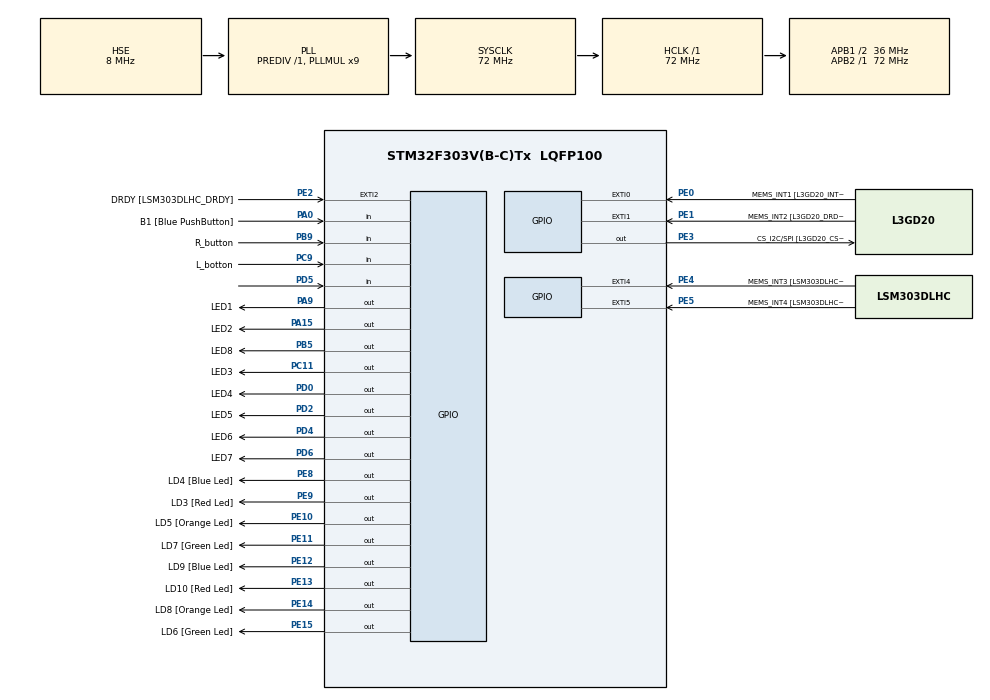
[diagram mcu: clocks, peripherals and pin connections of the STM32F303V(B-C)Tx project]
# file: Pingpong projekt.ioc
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Mcu.Family=STM32F3
Mcu.Name=STM32F303V(B-C)Tx
Mcu.Package=LQFP100
NVIC.PriorityGroup=NVIC_PRIORITYGROUP_0
PA0.GPIO_Label=B1 [Blue PushButton]
PA0.GPIO_Mode=GPIO_MODE_INPUT
PA0.GPIO_PuPd=GPIO_NOPULL
PA0.Signal=GPIO_Input
PA11.GPIO_Label=DM
PA11.Signal=USB_DM
PA12.GPIO_Label=DP
PA12.Signal=USB_DP
PA13.GPIO_Label=SWDIO
PA13.Signal=SYS_JTMS-SWDIO
PA14.GPIO_Label=SWCLK
PA14.Signal=SYS_JTCK-SWCLK
PA15.GPIO_Label=LED2
PA15.GPIO_Speed=GPIO_SPEED_FREQ_MEDIUM
PA15.Signal=GPIO_Output
PA5.GPIO_Label=SPI1_SCK [L3GD20_SCL/SPC]
PA5.GPIO_Mode=GPIO_MODE_AF_PP
PA5.GPIO_PuPd=GPIO_NOPULL
PA5.GPIO_Speed=GPIO_SPEED_FREQ_LOW
PA5.Signal=SPI1_SCK
PA6.GPIO_Label=SPI1_MISO [L3GD20_SA0/SDO]
PA6.GPIO_Mode=GPIO_MODE_AF_PP
PA6.GPIO_PuPd=GPIO_NOPULL
PA6.GPIO_Speed=GPIO_SPEED_FREQ_LOW
PA6.Signal=SPI1_MISO
PA7.GPIO_Label=SPI1_MISO [L3GD20_SDA/SDI/SDO]
PA7.GPIO_Mode=GPIO_MODE_AF_PP
PA7.GPIO_PuPd=GPIO_NOPULL
PA7.GPIO_Speed=GPIO_SPEED_FREQ_LOW
PA7.Signal=SPI1_MOSI
PA9.GPIO_Label=LED1
PA9.GPIO_Speed=GPIO_SPEED_FREQ_MEDIUM
PA9.Signal=GPIO_Output
PB3.GPIO_Label=SWO
PB3.Signal=SYS_JTDO-TRACESWO
PB5.GPIO_Label=LED8
PB5.GPIO_Speed=GPIO_SPEED_FREQ_MEDIUM
PB5.Signal=GPIO_Output
PB6.GPIO_FM6=__NULL
PB6.GPIO_Label=I2C1_SCL [LSM303DLHC_SCL]
PB6.GPIO_Mode=GPIO_MODE_AF_OD
PB6.GPIO_PuPd=GPIO_NOPULL
PB6.GPIO_Speed=GPIO_SPEED_FREQ_LOW
PB6.Signal=I2C1_SCL
PB7.GPIO_FM7=__NULL
PB7.GPIO_Label=I2C1_SDA [LSM303DLHC_SDA]
PB7.GPIO_Mode=GPIO_MODE_AF_OD
PB7.GPIO_PuPd=GPIO_NOPULL
PB7.GPIO_Speed=GPIO_SPEED_FREQ_LOW
PB7.Signal=I2C1_SDA
PB9.GPIO_Label=R_button
PB9.Signal=GPIO_Input
PC11.GPIO_Label=LED3
PC11.GPIO_Speed=GPIO_SPEED_FREQ_MEDIUM
PC11.Signal=GPIO_Output
PC14-OSC32_IN.GPIO_Label=OSC32_IN
PC14-OSC32_IN.Signal=RCC_OSC32_IN
PC15-OSC32_OUT.GPIO_Label=OSC32_OUT
PC15-OSC32_OUT.Signal=RCC_OSC32_OUT
PC9.GPIO_Label=L_botton
PC9.Signal=GPIO_Input
PD0.GPIO_Label=LED4
PD0.GPIO_Speed=GPIO_SPEED_FREQ_MEDIUM
PD0.Signal=GPIO_Output
PD2.GPIO_Label=LED5
PD2.GPIO_Speed=GPIO_SPEED_FREQ_MEDIUM
PD2.Signal=GPIO_Output
PD4.GPIO_Label=LED6
PD4.GPIO_Speed=GPIO_SPEED_FREQ_MEDIUM
PD4.Signal=GPIO_Output
PD5.Signal=GPIO_Input
PD6.GPIO_Label=LED7
PD6.GPIO_Speed=GPIO_SPEED_FREQ_MEDIUM
PD6.Signal=GPIO_Output
PE0.GPIO_Label=MEMS_INT1 [L3GD20_INT1]
PE0.GPIO_ModeDefaultEXTI=GPIO_MODE_EVT_RISING
PE0.GPIO_PuPd=GPIO_NOPULL
PE0.Signal=GPXTI0
PE1.GPIO_Label=MEMS_INT2 [L3GD20_DRDY/INT2]
PE1.GPIO_ModeDefaultEXTI=GPIO_MODE_EVT_RISING
PE1.GPIO_PuPd=GPIO_NOPULL
PE1.Signal=GPXTI1
PE10.GPIO_Label=LD5 [Orange Led]
PE10.GPIO_ModeDefaultOutputPP=GPIO_MODE_OUTPUT_PP
PE10.GPIO_PuPd=GPIO_NOPULL
PE10.GPIO_Speed=GPIO_SPEED_FREQ_LOW
PE10.Signal=GPIO_Output
PE11.GPIO_Label=LD7 [Green Led]
PE11.GPIO_ModeDefaultOutputPP=GPIO_MODE_OUTPUT_PP
PE11.GPIO_PuPd=GPIO_NOPULL
PE11.GPIO_Speed=GPIO_SPEED_FREQ_LOW
PE11.Signal=GPIO_Output
PE12.GPIO_Label=LD9 [Blue Led]
PE12.GPIO_ModeDefaultOutputPP=GPIO_MODE_OUTPUT_PP
PE12.GPIO_PuPd=GPIO_NOPULL
PE12.GPIO_Speed=GPIO_SPEED_FREQ_LOW
PE12.Signal=GPIO_Output
PE13.GPIO_Label=LD10 [Red Led]
PE13.GPIO_ModeDefaultOutputPP=GPIO_MODE_OUTPUT_PP
PE13.GPIO_PuPd=GPIO_NOPULL
PE13.GPIO_Speed=GPIO_SPEED_FREQ_LOW
PE13.Signal=GPIO_Output
PE14.GPIO_Label=LD8 [Orange Led]
PE14.GPIO_ModeDefaultOutputPP=GPIO_MODE_OUTPUT_PP
PE14.GPIO_PuPd=GPIO_NOPULL
PE14.GPIO_Speed=GPIO_SPEED_FREQ_LOW
PE14.Signal=GPIO_Output
PE15.GPIO_Label=LD6 [Green Led]
PE15.GPIO_ModeDefaultOutputPP=GPIO_MODE_OUTPUT_PP
PE15.GPIO_PuPd=GPIO_NOPULL
PE15.GPIO_Speed=GPIO_SPEED_FREQ_LOW
PE15.Signal=GPIO_Output
PE2.GPIO_Label=DRDY [LSM303DLHC_DRDY]
PE2.GPIO_ModeDefaultEXTI=GPIO_MODE_EVT_RISING
PE2.GPIO_PuPd=GPIO_NOPULL
PE2.Signal=GPXTI2
PE3.GPIO_Label=CS_I2C/SPI [L3GD20_CS_I2C/SPI]
PE3.GPIO_ModeDefaultOutputPP=GPIO_MODE_OUTPUT_PP
PE3.GPIO_PuPd=GPIO_NOPULL
PE3.GPIO_Speed=GPIO_SPEED_FREQ_LOW
PE3.Signal=GPIO_Output
PE4.GPIO_Label=MEMS_INT3 [LSM303DLHC_INT1]
PE4.GPIO_ModeDefaultEXTI=GPIO_MODE_EVT_RISING
PE4.GPIO_PuPd=GPIO_NOPULL
PE4.Signal=GPXTI4
PE5.GPIO_Label=MEMS_INT4 [LSM303DLHC_INT2]
PE5.GPIO_ModeDefaultEXTI=GPIO_MODE_EVT_RISING
PE5.GPIO_PuPd=GPIO_NOPULL
PE5.Signal=GPXTI5
PE8.GPIO_Label=LD4 [Blue Led]
PE8.GPIO_ModeDefaultOutputPP=GPIO_MODE_OUTPUT_PP
PE8.GPIO_PuPd=GPIO_NOPULL
PE8.GPIO_Speed=GPIO_SPEED_FREQ_LOW
PE8.Signal=GPIO_Output
PE9.GPIO_Label=LD3 [Red Led]
PE9.GPIO_ModeDefaultOutputPP=GPIO_MODE_OUTPUT_PP
PE9.GPIO_PuPd=GPIO_NOPULL
PE9.GPIO_Speed=GPIO_SPEED_FREQ_LOW
PE9.Signal=GPIO_Output
PF0-OSC_IN.Mode=HSE-External-Oscillator
PF0-OSC_IN.Signal=RCC_OSC_IN
PF1-OSC_OUT.GPIO_Label=OSC_OUT
PF1-OSC_OUT.Mode=HSE-External-Oscillator
PF1-OSC_OUT.Signal=RCC_OSC_OUT
ProjectManager.HeapSize=0x200
ProjectManager.StackSize=0x400
ProjectManager.TargetToolchain=EWARM
RCC.AHBFreq_Value=72000000
RCC.APB1CLKDivider=RCC_HCLK_DIV2
RCC.APB1Freq_Value=36000000
RCC.APB1TimFreq_Value=72000000
RCC.APB2Freq_Value=72000000
RCC.APB2TimFreq_Value=72000000
RCC.CortexFreq_Value=72000000
RCC.HCLKFreq_Value=72000000
RCC.HSE_VALUE=8000000
RCC.HSIState=RCC_HSI_ON
RCC.HSI_VALUE=8000000
RCC.LSE_VALUE=32768
RCC.PLLMUL=RCC_PLL_MUL9
RCC.PLLSourceVirtual=RCC_PLLSOURCE_HSE
RCC.SYSCLKFreq_VALUE=72000000
RCC.SYSCLKSourceVirtual=RCC_SYSCLKSOURCE_PLLCLK
RCC.USBFreq_Value=72000000
board=STM32F3DISCOVERY

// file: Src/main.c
/**
  ******************************************************************************
  * File Name          : main.c
  * Description        : Main program body
  ******************************************************************************
  *
  * COPYRIGHT(c) 2017 STMicroelectronics
  *
  * Redistribution and use in source and binary forms, with or without modification,
  * are permitted provided that the following conditions are met:
  *   1. Redistributions of source code must retain the above copyright notice,
  *      this list of conditions and the following disclaimer.
  *   2. Redistributions in binary form must reproduce the above copyright notice,
  *      this list of conditions and the following disclaimer in the documentation
  *      and/or other materials provided with the distribution.
  *   3. Neither the name of STMicroelectronics nor the names of its contributors
  *      may be used to endorse or promote products derived from this software
  *      without specific prior written permission.
  *
  * THIS SOFTWARE IS PROVIDED BY THE COPYRIGHT HOLDERS AND CONTRIBUTORS "AS IS"
  * AND ANY EXPRESS OR IMPLIED WARRANTIES, INCLUDING, BUT NOT LIMITED TO, THE
  * IMPLIED WARRANTIES OF MERCHANTABILITY AND FITNESS FOR A PARTICULAR PURPOSE ARE
  * DISCLAIMED. IN NO EVENT SHALL THE COPYRIGHT HOLDER OR CONTRIBUTORS BE LIABLE
  * FOR ANY DIRECT, INDIRECT, INCIDENTAL, SPECIAL, EXEMPLARY, OR CONSEQUENTIAL
  * DAMAGES (INCLUDING, BUT NOT LIMITED TO, PROCUREMENT OF SUBSTITUTE GOODS OR
  * SERVICES; LOSS OF USE, DATA, OR PROFITS; OR BUSINESS INTERRUPTION) HOWEVER
  * CAUSED AND ON ANY THEORY OF LIABILITY, WHETHER IN CONTRACT, STRICT LIABILITY,
  * OR TORT (INCLUDING NEGLIGENCE OR OTHERWISE) ARISING IN ANY WAY OUT OF THE USE
  * OF THIS SOFTWARE, EVEN IF ADVISED OF THE POSSIBILITY OF SUCH DAMAGE.
  *
  ******************************************************************************
  */
#include "main.h"
#include "stm32f3xx_hal.h"
#include "stdbool.h"
#include "Pingpong_functions.c"

/* USER CODE BEGIN PV */
/* Private variables ---------------------------------------------------------*/

/* USER CODE END PV */

void SystemClock_Config(void);
void Error_Handler(void);
static void MX_GPIO_Init(void);

/* USER CODE BEGIN PFP */
/* Private function prototypes -----------------------------------------------*/

typedef enum
{ Start,
MoveRight,
MoveLeft,
ShowPoints
} states;

states State, NextState;

/* USER CODE END PFP */

int main(void)
{

  bool ButtonPressed; // To remember that button is pressed
  bool surf;

  uint32_t Varv, Speed; // Ball speed
  uint8_t Led; // LED nr

  State= Start; // Initiate State to Start
  NextState= Start;
  int lp = 0;
  int rp = 0;

 Speed= 500000; // Number of loops

  /* Reset of all peripherals, Initializes the Flash interface and the Systick. */
  HAL_Init();

  /* Configure the system clock */
  SystemClock_Config();

  /* Initialize all configured peripherals */
  MX_GPIO_Init();

  while (1)
 {
   State = NextState;

   switch (State) // State machine
   {
     case Start:

     Led_on(0); // Turn off all LEDs
     HAL_GPIO_WritePin(LED1_GPIO_Port, LED1_Pin, GPIO_PIN_SET);
     HAL_GPIO_WritePin(LED8_GPIO_Port, LED8_Pin, GPIO_PIN_SET);
     HAL_Delay(1);
     Led_on(0);
     HAL_Delay(10);

     if ( L_hit() == true ) // L serve
     {
       Led = 1;
       surf = false;
       NextState= MoveRight;
       while ( L_hit() == true ); // wait until button is released
     }
     else if ( R_hit() == true ) // R serve
     {
       surf = true;
       Led = 8;
       NextState= MoveLeft;

       while ( R_hit() == true ); // wait until button is released
     }
     else
     NextState = Start; // Stay in Start state
     break;

 case MoveRight:
 {
   Led_on(Led);
   Varv = Speed;

   while( Varv != 0 )
     {
       if ( R_hit() ) ButtonPressed = true; // R hit
       Varv--;
     }

     if ( ButtonPressed ) // R pressed
       {
         if ( Led == 8 ) // and LED8 activ
         {
           NextState=MoveLeft; // return ball
           Led=7;
           Speed -= 9000;
         }
         else
         {
           rp++;
           Show_points (rp, lp);
           NextState = ShowPoints;    // hit to early
           Speed = 500000;
         }
      }
      else
      {
        if ( Led == 9 ) // no hit or to late
        {
          rp++;
          Show_points (rp, lp);
          NextState = ShowPoints;
          Speed = 500000;

        }
        else
         NextState = MoveRight; // ball continues to move right
      }
      if ( !ButtonPressed ) Led++; // prepare to turn next LED on
      ButtonPressed=false;
 }
 break;

 case MoveLeft:
 {
   Led_on(Led);
   Varv = Speed;

   while(Varv != 0)
   {
     if ( L_hit() ) ButtonPressed = true; // L hit
      Varv--;
   }
   if ( ButtonPressed ) // L pressed
   {
     if ( Led == 1 ) // and LED1 activ
     {
       NextState=MoveRight; // return ball
       Led=2;
       Speed -= 9000;
     }
     else
     {
       lp++;
       Show_points (rp, lp);
       NextState = ShowPoints;     // hit to early    // g�r till showpoints
       Speed = 500000;
    }
   }
   else
   {
     if ( Led == 0 ) // no hit or to late
     {
       lp++;
       Show_points (rp, lp);
       NextState = ShowPoints;     // g�r tillshowpoints
       Speed = 500000;

     }
     else
     NextState = MoveLeft; // ball continues to move left
   }
   if ( !ButtonPressed ) Led--; // prepare to turn next LED on
   ButtonPressed=false;

 }
 break;

/* case ShowPoints:
{
  Show_points (lp, rp);
  NextState = Start;

  if (rp== 4)
  {
    rp = 0;
    lp = 0;
  }

  if (lp== 4)
  {
    lp = 0;
    rp = 0;
  }

}
break; */

  case ShowPoints:
   {
     if (rp == 4 || lp == 4)
     {
       rp = 0;
       lp = 0;
       NextState = Start;
     }
     else if (rp !=4 || lp != 4)
     {
        if  (surf)
              {
                Led_on(1);
                HAL_Delay(1);
                Led_on(0);
                HAL_Delay(10);
              }
              else
              {
                Led_on(8);
                HAL_Delay(1);
                Led_on(0);
                HAL_Delay(10);
              }

              if (surf && L_hit() )
              {
                 surf = false;
                 Led =1;

                  NextState =MoveRight ;
                 while ( L_hit() == true );
              }

              else if(!surf && R_hit() )
              {
                surf = true;
                Led = 8;
                Led_on(8);

                NextState = MoveLeft;
               while ( R_hit() == true );

              }
          }

           else
            NextState = ShowPoints; // Stay in Vinnare state
            break;
        }

 default:
 break;
 }
 }
 }

  /* USER CODE END 3 */

/** System Clock Configuration
*/
void SystemClock_Config(void)
{

  RCC_OscInitTypeDef RCC_OscInitStruct;
  RCC_ClkInitTypeDef RCC_ClkInitStruct;

    /**Initializes the CPU, AHB and APB busses clocks
    */
  RCC_OscInitStruct.OscillatorType = RCC_OSCILLATORTYPE_HSE;
  RCC_OscInitStruct.HSEState = RCC_HSE_ON;
  RCC_OscInitStruct.HSEPredivValue = RCC_HSE_PREDIV_DIV1;
  RCC_OscInitStruct.HSIState = RCC_HSI_ON;
  RCC_OscInitStruct.PLL.PLLState = RCC_PLL_ON;
  RCC_OscInitStruct.PLL.PLLSource = RCC_PLLSOURCE_HSE;
  RCC_OscInitStruct.PLL.PLLMUL = RCC_PLL_MUL9;
  if (HAL_RCC_OscConfig(&RCC_OscInitStruct) != HAL_OK)
  {
    Error_Handler();
  }

    /**Initializes the CPU, AHB and APB busses clocks
    */
  RCC_ClkInitStruct.ClockType = RCC_CLOCKTYPE_HCLK|RCC_CLOCKTYPE_SYSCLK
                              |RCC_CLOCKTYPE_PCLK1|RCC_CLOCKTYPE_PCLK2;
  RCC_ClkInitStruct.SYSCLKSource = RCC_SYSCLKSOURCE_PLLCLK;
  RCC_ClkInitStruct.AHBCLKDivider = RCC_SYSCLK_DIV1;
  RCC_ClkInitStruct.APB1CLKDivider = RCC_HCLK_DIV2;
  RCC_ClkInitStruct.APB2CLKDivider = RCC_HCLK_DIV1;

  if (HAL_RCC_ClockConfig(&RCC_ClkInitStruct, FLASH_LATENCY_2) != HAL_OK)
  {
    Error_Handler();
  }

    /**Configure the Systick interrupt time
    */
  HAL_SYSTICK_Config(HAL_RCC_GetHCLKFreq()/1000);

    /**Configure the Systick
    */
  HAL_SYSTICK_CLKSourceConfig(SYSTICK_CLKSOURCE_HCLK);

  /* SysTick_IRQn interrupt configuration */
  HAL_NVIC_SetPriority(SysTick_IRQn, 0, 0);
}

/** Configure pins as
        * Analog
        * Input
        * Output
        * EVENT_OUT
        * EXTI
     PA5   ------> SPI1_SCK
     PA6   ------> SPI1_MISO
     PA7   ------> SPI1_MOSI
     PA11   ------> USB_DM
     PA12   ------> USB_DP
     PB6   ------> I2C1_SCL
     PB7   ------> I2C1_SDA
*/
static void MX_GPIO_Init(void)
{

  GPIO_InitTypeDef GPIO_InitStruct;

  /* GPIO Ports Clock Enable */
  __HAL_RCC_GPIOE_CLK_ENABLE();
  __HAL_RCC_GPIOC_CLK_ENABLE();
  __HAL_RCC_GPIOF_CLK_ENABLE();
  __HAL_RCC_GPIOA_CLK_ENABLE();
  __HAL_RCC_GPIOD_CLK_ENABLE();
  __HAL_RCC_GPIOB_CLK_ENABLE();

  /*Configure GPIO pins : DRDY_Pin MEMS_INT3_Pin MEMS_INT4_Pin MEMS_INT1_Pin
                           MEMS_INT2_Pin */
  GPIO_InitStruct.Pin = DRDY_Pin|MEMS_INT3_Pin|MEMS_INT4_Pin|MEMS_INT1_Pin
                          |MEMS_INT2_Pin;
  GPIO_InitStruct.Mode = GPIO_MODE_EVT_RISING;
  GPIO_InitStruct.Pull = GPIO_NOPULL;
  HAL_GPIO_Init(GPIOE, &GPIO_InitStruct);

  /*Configure GPIO pins : CS_I2C_SPI_Pin LD4_Pin LD3_Pin LD5_Pin
                           LD7_Pin LD9_Pin LD10_Pin LD8_Pin
                           LD6_Pin */
  GPIO_InitStruct.Pin = CS_I2C_SPI_Pin|LD4_Pin|LD3_Pin|LD5_Pin
                          |LD7_Pin|LD9_Pin|LD10_Pin|LD8_Pin
                          |LD6_Pin;
  GPIO_InitStruct.Mode = GPIO_MODE_OUTPUT_PP;
  GPIO_InitStruct.Pull = GPIO_NOPULL;
  GPIO_InitStruct.Speed = GPIO_SPEED_FREQ_LOW;
  HAL_GPIO_Init(GPIOE, &GPIO_InitStruct);

  /*Configure GPIO pin : B1_Pin */
  GPIO_InitStruct.Pin = B1_Pin;
  GPIO_InitStruct.Mode = GPIO_MODE_INPUT;
  GPIO_InitStruct.Pull = GPIO_NOPULL;
  HAL_GPIO_Init(B1_GPIO_Port, &GPIO_InitStruct);

  /*Configure GPIO pins : SPI1_SCK_Pin SPI1_MISO_Pin SPI1_MISOA7_Pin */
  GPIO_InitStruct.Pin = SPI1_SCK_Pin|SPI1_MISO_Pin|SPI1_MISOA7_Pin;
  GPIO_InitStruct.Mode = GPIO_MODE_AF_PP;
  GPIO_InitStruct.Pull = GPIO_NOPULL;
  GPIO_InitStruct.Speed = GPIO_SPEED_FREQ_LOW;
  GPIO_InitStruct.Alternate = GPIO_AF5_SPI1;
  HAL_GPIO_Init(GPIOA, &GPIO_InitStruct);

  /*Configure GPIO pin : L_botton_Pin */
  GPIO_InitStruct.Pin = L_botton_Pin;
  GPIO_InitStruct.Mode = GPIO_MODE_INPUT;
  GPIO_InitStruct.Pull = GPIO_NOPULL;
  HAL_GPIO_Init(L_botton_GPIO_Port, &GPIO_InitStruct);

  /*Configure GPIO pins : LED1_Pin LED2_Pin */
  GPIO_InitStruct.Pin = LED1_Pin|LED2_Pin;
  GPIO_InitStruct.Mode = GPIO_MODE_OUTPUT_PP;
  GPIO_InitStruct.Pull = GPIO_NOPULL;
  GPIO_InitStruct.Speed = GPIO_SPEED_FREQ_MEDIUM;
  HAL_GPIO_Init(GPIOA, &GPIO_InitStruct);

  /*Configure GPIO pins : DM_Pin DP_Pin */
  GPIO_InitStruct.Pin = DM_Pin|DP_Pin;
  GPIO_InitStruct.Mode = GPIO_MODE_AF_PP;
  GPIO_InitStruct.Pull = GPIO_NOPULL;
  GPIO_InitStruct.Speed = GPIO_SPEED_FREQ_HIGH;
  GPIO_InitStruct.Alternate = GPIO_AF14_USB;
  HAL_GPIO_Init(GPIOA, &GPIO_InitStruct);

  /*Configure GPIO pin : LED3_Pin */
  GPIO_InitStruct.Pin = LED3_Pin;
  GPIO_InitStruct.Mode = GPIO_MODE_OUTPUT_PP;
  GPIO_InitStruct.Pull = GPIO_NOPULL;
  GPIO_InitStruct.Speed = GPIO_SPEED_FREQ_MEDIUM;
  HAL_GPIO_Init(LED3_GPIO_Port, &GPIO_InitStruct);

  /*Configure GPIO pins : LED4_Pin LED5_Pin LED6_Pin LED7_Pin */
  GPIO_InitStruct.Pin = LED4_Pin|LED5_Pin|LED6_Pin|LED7_Pin;
  GPIO_InitStruct.Mode = GPIO_MODE_OUTPUT_PP;
  GPIO_InitStruct.Pull = GPIO_NOPULL;
  GPIO_InitStruct.Speed = GPIO_SPEED_FREQ_MEDIUM;
  HAL_GPIO_Init(GPIOD, &GPIO_InitStruct);

  /*Configure GPIO pin : PD5 */
  GPIO_InitStruct.Pin = GPIO_PIN_5;
  GPIO_InitStruct.Mode = GPIO_MODE_INPUT;
  GPIO_InitStruct.Pull = GPIO_NOPULL;
  HAL_GPIO_Init(GPIOD, &GPIO_InitStruct);

  /*Configure GPIO pin : LED8_Pin */
  GPIO_InitStruct.Pin = LED8_Pin;
  GPIO_InitStruct.Mode = GPIO_MODE_OUTPUT_PP;
  GPIO_InitStruct.Pull = GPIO_NOPULL;
  GPIO_InitStruct.Speed = GPIO_SPEED_FREQ_MEDIUM;
  HAL_GPIO_Init(LED8_GPIO_Port, &GPIO_InitStruct);

  /*Configure GPIO pins : I2C1_SCL_Pin I2C1_SDA_Pin */
  GPIO_InitStruct.Pin = I2C1_SCL_Pin|I2C1_SDA_Pin;
  GPIO_InitStruct.Mode = GPIO_MODE_AF_OD;
  GPIO_InitStruct.Pull = GPIO_PULLUP;
  GPIO_InitStruct.Speed = GPIO_SPEED_FREQ_LOW;
  GPIO_InitStruct.Alternate = GPIO_AF4_I2C1;
  HAL_GPIO_Init(GPIOB, &GPIO_InitStruct);

  /*Configure GPIO pin : R_button_Pin */
  GPIO_InitStruct.Pin = R_button_Pin;
  GPIO_InitStruct.Mode = GPIO_MODE_INPUT;
  GPIO_InitStruct.Pull = GPIO_NOPULL;
  HAL_GPIO_Init(R_button_GPIO_Port, &GPIO_InitStruct);

  /*Configure GPIO pin Output Level */
  HAL_GPIO_WritePin(GPIOE, CS_I2C_SPI_Pin|LD4_Pin|LD3_Pin|LD5_Pin
                          |LD7_Pin|LD9_Pin|LD10_Pin|LD8_Pin
                          |LD6_Pin, GPIO_PIN_RESET);

  /*Configure GPIO pin Output Level */
  HAL_GPIO_WritePin(GPIOA, LED1_Pin|LED2_Pin, GPIO_PIN_RESET);

  /*Configure GPIO pin Output Level */
  HAL_GPIO_WritePin(LED3_GPIO_Port, LED3_Pin, GPIO_PIN_RESET);

  /*Configure GPIO pin Output Level */
  HAL_GPIO_WritePin(GPIOD, LED4_Pin|LED5_Pin|LED6_Pin|LED7_Pin, GPIO_PIN_RESET);

  /*Configure GPIO pin Output Level */
  HAL_GPIO_WritePin(LED8_GPIO_Port, LED8_Pin, GPIO_PIN_RESET);

}

void Error_Handler(void)
{
  while(1)
  {
  }
}

/************************ (C) COPYRIGHT STMicroelectronics *****END OF FILE****/
